# LPC55S66_cm33_core1 register map
Vendor: nxp.com; File version: 1.0
CPU: CM33 r2p0, little endian, no MPU, no FPU, VTOR, 3 interrupt priority bits
Registers are 32-bit, read-write, reset 0x0 unless marked. A register's access mark holds for its fields unless they carry their own. Offsets are from the block's base; [hi:lo] are bit positions; {n}, {i} and the like mark numbered series; 'fields as' and 'values as' point back to an identical list.

## ADC0 — ADC
Base 0x400A0000
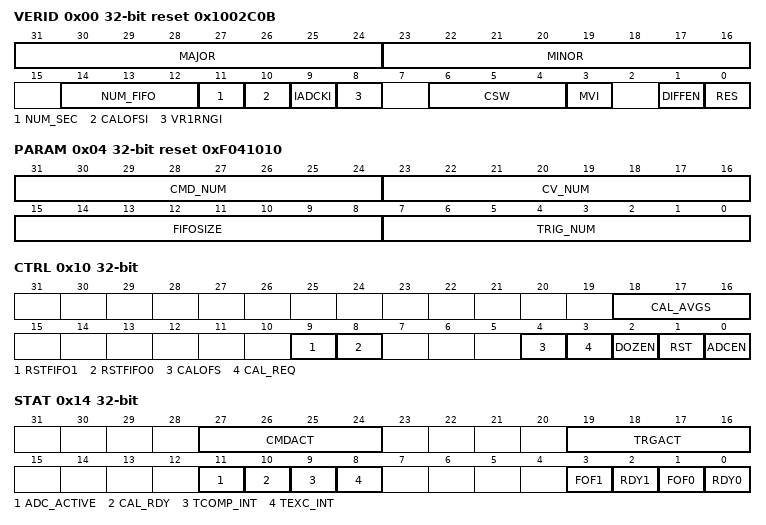
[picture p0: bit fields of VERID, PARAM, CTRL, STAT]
0x00 VERID ro reset 0x1002C0B — Version ID Register
  [31:24] MAJOR — Major Version Number
  [23:16] MINOR — Minor Version Number
  [14:12] NUM_FIFO — Number of FIFOs
    0=N/A; 1=This design supports one result FIFO; 2=This design supports two result FIFOs; 3=This design supports three result FIFOs; 4=This design supports four result FIFOs
  [11] NUM_SEC — Number of Single Ended Outputs Supported
    0=This design supports one single ended conversion at a time; 1=This design supports two simultanious single ended conversions
  [10] CALOFSI — Calibration Function Implemented
    0=Calibration Not Implemented; 1=Calibration Implemented
  [9] IADCKI — Internal ADC Clock implemented
    0=Internal clock source not implemented; 1=Internal clock source (and CFG[ADCKEN]) implemented
  [8] VR1RNGI — Voltage Reference 1 Range Control Bit Implemented
    0=Range control not required. CFG[VREF1RNG] is not implemented.; 1=Range control required. CFG[VREF1RNG] is implemented.
  [6:4] CSW — Channel Scale Width
    0=Channel scaling not supported; 1=Channel scaling supported. 1-bit CSCALE control field.; 6=Channel scaling supported. 6-bit CSCALE control field.
  [3] MVI — Multi Vref Implemented
    0=Single voltage reference high (VREFH) input supported; 1=Multiple voltage reference high (VREFH) inputs supported
  [1] DIFFEN — Differential Supported
    0=Differential operation not supported; 1=Differential operation supported. CMDLa[CTYPE] controls fields implemented.
  [0] RES — Resolution
    0=Up to 13-bit differential/12-bit single ended resolution supported; 1=Up to 16-bit differential/16-bit single ended resolution supported
0x04 PARAM ro reset 0xF041010 — Parameter Register
  [31:24] CMD_NUM — Command Buffer Number
  [23:16] CV_NUM — Compare Value Number
  [15:8] FIFOSIZE — Result FIFO Depth
    1=Result FIFO depth = 1 dataword; 4=Result FIFO depth = 4 datawords; 8=Result FIFO depth = 8 datawords; 16=Result FIFO depth = 16 datawords; 32=Result FIFO depth = 32 datawords; 64=Result FIFO depth = 64 datawords
  [7:0] TRIG_NUM — Trigger Number
0x10 CTRL — ADC Control Register
  [18:16] CAL_AVGS — Auto-Calibration Averages
    0=Single conversion; 1=2 conversions averaged; 2=4 conversions averaged; 3=8 conversions averaged; 4=16 conversions averaged; 5=32 conversions averaged; 6=64 conversions averaged; 7=128 conversions averaged
  [9] RSTFIFO1 — Reset FIFO 1
    0=No effect; 1=FIFO 1 is reset
  [8] RSTFIFO0 — Reset FIFO 0
    0=No effect; 1=FIFO 0 is reset
  [4] CALOFS — Configure for offset calibration function
    0=Calibration function disabled; 1=Request for offset calibration function
  [3] CAL_REQ — Auto-Calibration Request
    0=No request for auto-calibration has been made; 1=A request for auto-calibration has been made
  [2] DOZEN — Doze Enable
    0=ADC is enabled in Doze mode; 1=ADC is disabled in Doze mode
  [1] RST — Software Reset
    0=ADC logic is not reset; 1=ADC logic is reset
  [0] ADCEN — ADC Enable
    0=ADC is disabled; 1=ADC is enabled
0x14 STAT — ADC Status Register
  [27:24] CMDACT ro — Command Active
    0=No command is currently in progress; 1=Command 1 currently being executed; 2=Command 2 currently being executed; {v}=Associated command number is currently being executed (v=3..9)
  [19:16] TRGACT ro — Trigger Active
    0=Command (sequence) associated with Trigger 0 currently being executed; 1=Command (sequence) associated with Trigger 1 currently being executed; 2=Command (sequence) associated with Trigger 2 currently being executed; {v}=Command (sequence) from the associated Trigger number is currently being executed (v=3..9)
  [11] ADC_ACTIVE ro
    0=The ADC is IDLE. There are no pending triggers to service and no active commands are being processed.; 1=The ADC is processing a conversion, running through the power up delay, or servicing a trigger
  [10] CAL_RDY ro — Calibration Ready
    0=Calibration is incomplete or hasn't been ran; 1=The ADC is calibrated
  [9] TCOMP_INT write-1-clears — Interrupt Flag For Trigger Completion
    0=Either IE[TCOMP_IE] is set to 0, or no trigger sequences have run to completion; 1=Trigger sequence has been completed and all data is stored in the associated FIFO
  [8] TEXC_INT write-1-clears — Interrupt Flag For High Priority Trigger Exception
    0=No trigger exceptions have occurred; 1=A trigger exception has occurred and is pending acknowledgement
  [3] FOF1 write-1-clears — Result FIFO1 Overflow Flag
    0=No result FIFO1 overflow has occurred since the last time the flag was cleared; 1=At least one result FIFO1 overflow has occurred since the last time the flag was cleared
  [2] RDY1 ro — Result FIFO1 Ready Flag
    0=Result FIFO1 data level not above watermark level; 1=Result FIFO1 holding data above watermark level
  [1] FOF0 write-1-clears — Result FIFO 0 Overflow Flag
    0=No result FIFO 0 overflow has occurred since the last time the flag was cleared; 1=At least one result FIFO 0 overflow has occurred since the last time the flag was cleared
  [0] RDY0 ro — Result FIFO 0 Ready Flag
    0=Result FIFO 0 data level not above watermark level; 1=Result FIFO 0 holding data above watermark level
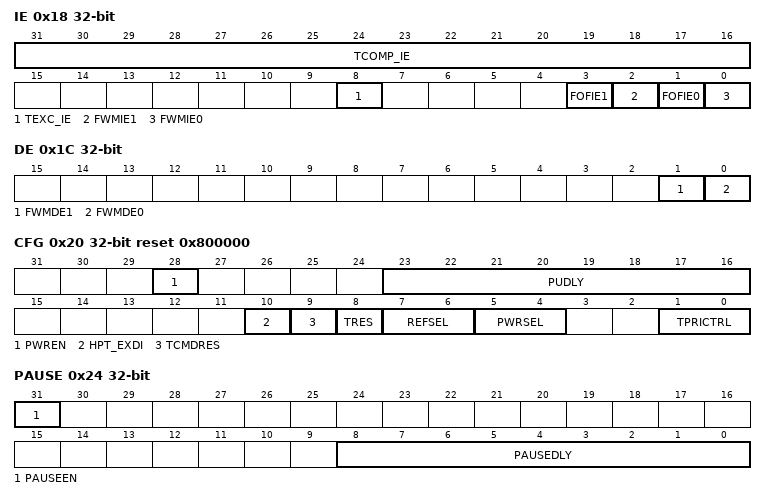
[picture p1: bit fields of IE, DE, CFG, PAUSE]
0x18 IE — Interrupt Enable Register
  [31:16] TCOMP_IE — Trigger Completion Interrupt Enable
    0=Trigger completion interrupts are disabled; 1=Trigger completion interrupts are enabled for trigger source 0 only; 2=Trigger completion interrupts are enabled for trigger source 1 only; {v}=Associated trigger completion interrupts are enabled (v=3..9); 0xFFFF=Trigger completion interrupts are enabled for every trigger source
  [8] TEXC_IE — Trigger Exception Interrupt Enable
    0=Trigger exception interrupts are disabled; 1=Trigger exception interrupts are enabled
  [3] FOFIE1 — Result FIFO1 Overflow Interrupt Enable
    values as STAT.FOF1
  [2] FWMIE1 — FIFO1 Watermark Interrupt Enable
    0=FIFO1 watermark interrupts are not enabled; 1=FIFO1 watermark interrupts are enabled
  [1] FOFIE0 — Result FIFO 0 Overflow Interrupt Enable
    0=FIFO 0 overflow interrupts are not enabled; 1=FIFO 0 overflow interrupts are enabled
  [0] FWMIE0 — FIFO 0 Watermark Interrupt Enable
    0=FIFO 0 watermark interrupts are not enabled; 1=FIFO 0 watermark interrupts are enabled
0x1C DE — DMA Enable Register
  [1] FWMDE1 — FIFO1 Watermark DMA Enable
    0=DMA request disabled; 1=DMA request enabled
  [0] FWMDE0 — FIFO 0 Watermark DMA Enable
    0=DMA request disabled; 1=DMA request enabled
0x20 CFG reset 0x800000 — ADC Configuration Register
  [28] PWREN — ADC Analog Pre-Enable
    0=ADC analog circuits are only enabled while conversions are active. Performance is affected due to analog startup delays.; 1=ADC analog circuits are pre-enabled and ready to execute conversions without startup delays (at the cost of higher DC current consumption). A single power up delay (CFG[PUDLY]) is executed immediately once PWREN is set, and any detected trigger does not begin ADC operation until the power up delay time has passed. After this initial delay expires the analog will remain pre-enabled, and no additional delays will be executed.
  [23:16] PUDLY — Power Up Delay
  [10] HPT_EXDI — High Priority Trigger Exception Disable
    0=High priority trigger exceptions are enabled; 1=High priority trigger exceptions are disabled
  [9] TCMDRES — Trigger Command Resume
    0=Trigger sequences interrupted by a high priority trigger exception will be automatically restarted; 1=Trigger sequences interrupted by a high priority trigger exception will be resumed from the command executing before the exception
  [8] TRES — Trigger Resume Enable
    0=Trigger sequences interrupted by a high priority trigger exception will not be automatically resumed or restarted; 1=Trigger sequences interrupted by a high priority trigger exception will be automatically resumed or restarted
  [7:6] REFSEL — Voltage Reference Selection
    0=(Default) Option 1 setting; 1=Option 2 setting; 2=Option 3 setting
  [5:4] PWRSEL — Power Configuration Select
    0=Lowest power setting; 1=Higher power setting than 0b0; 2=Higher power setting than 0b1; 3=Highest power setting
  [1:0] TPRICTRL — ADC trigger priority control
    0=If a higher priority trigger is detected during command processing, the current conversion is aborted and the new command specified by the trigger is started; 1=If a higher priority trigger is received during command processing, the current command is stopped after after completing the current conversion. If averaging is enabled, the averaging loop will be completed. However, CMDHa[LOOP] will be ignored and the higher priority trigger will be serviced.; 2=If a higher priority trigger is received during command processing, the current command will be completed (averaging, looping, compare) before servicing the higher priority trigger
0x24 PAUSE — ADC Pause Register
  [31] PAUSEEN — PAUSE Option Enable
    0=Pause operation disabled; 1=Pause operation enabled
  [8:0] PAUSEDLY — Pause Delay
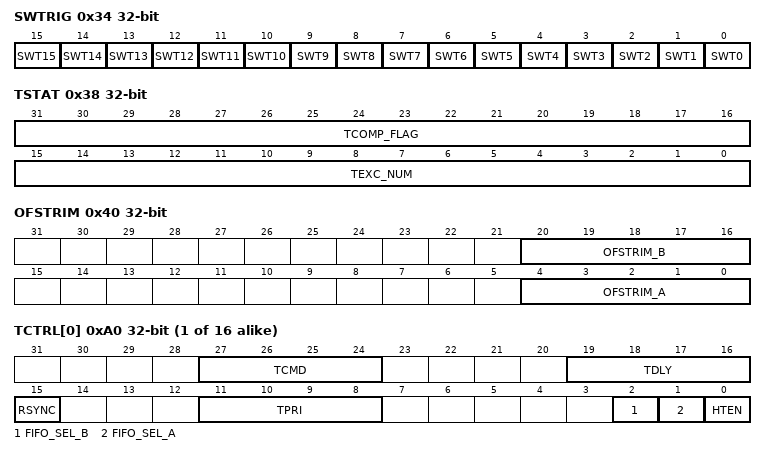
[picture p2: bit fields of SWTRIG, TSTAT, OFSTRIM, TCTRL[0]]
0x34 SWTRIG — Software Trigger Register
  [n] SWT{n} (n=0..15) — Software trigger {n} event
    0=No trigger {n} event generated; 1=Trigger {n} event generated
0x38 TSTAT — Trigger Status Register
  [31:16] TCOMP_FLAG write-1-clears — Trigger Completion Flag
    0=No triggers have been completed. Trigger completion interrupts are disabled.; 1=Trigger 0 has been completed and triger 0 has enabled completion interrupts; 2=Trigger 1 has been completed and triger 1 has enabled completion interrupts; {v}=Associated trigger sequence has completed and has enabled completion interrupts (v=3..9); 0xFFFF=Every trigger sequence has been completed and every trigger has enabled completion interrupts
  [15:0] TEXC_NUM write-1-clears — Trigger Exception Number
    0=No triggers have been interrupted by a high priority exception. Or CFG[TRES] = 1.; 1=Trigger 0 has been interrupted by a high priority exception; 2=Trigger 1 has been interrupted by a high priority exception; {v}=Associated trigger sequence has interrupted by a high priority exception (v=3..9); 0xFFFF=Every trigger sequence has been interrupted by a high priority exception
0x40 OFSTRIM — ADC Offset Trim Register
  [20:16] OFSTRIM_B — Trim for offset
  [4:0] OFSTRIM_A — Trim for offset
{0xA0+4i} TCTRL[{i}] (i=0..15) — Trigger Control Register
  [27:24] TCMD — Trigger command select
    0=Not a valid selection from the command buffer. Trigger event is ignored.; 1=CMD1 is executed; {v}=Corresponding CMD is executed (v=2..9); 15=CMD15 is executed
  [19:16] TDLY — Trigger delay select
  [15] RSYNC — Trigger Resync
  [11:8] TPRI — Trigger priority setting
    0=Set to highest priority, Level 1; {v}=Set to corresponding priority level (v=1..9); 15=Set to lowest priority, Level 16
  [2] FIFO_SEL_B — SAR Result Destination For Channel B
    0=Result written to FIFO 0; 1=Result written to FIFO 1
  [1] FIFO_SEL_A — SAR Result Destination For Channel A
    0=Result written to FIFO 0; 1=Result written to FIFO 1
  [0] HTEN — Trigger enable
    0=Hardware trigger source disabled; 1=Hardware trigger source enabled
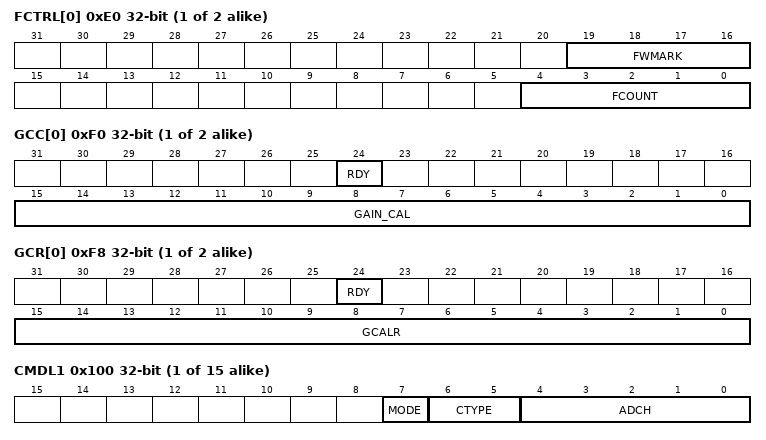
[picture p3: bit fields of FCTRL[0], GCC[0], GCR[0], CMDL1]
{0xE0+4i} FCTRL[{i}] (i=0..1) — FIFO Control Register
  [19:16] FWMARK — Watermark level selection
  [4:0] FCOUNT ro — Result FIFO counter
{0xF0+4i} GCC[{i}] (i=0..1) ro — Gain Calibration Control
  [24] RDY — Gain Calibration Value Valid
    0=The gain calibration value is invalid. Run the auto-calibration routine for this value to be written.; 1=The gain calibration value is valid. It should be used to update the GCRa[GCALR] register field.
  [15:0] GAIN_CAL — Gain Calibration Value
{0xF8+4i} GCR[{i}] (i=0..1) — Gain Calculation Result
  [24] RDY — Gain Calculation Ready
    0=The gain offset calculation value is invalid; 1=The gain calibration value is valid
  [15:0] GCALR — Gain Calculation Result
{0xF8+8i} CMDL{i} (i=1..15) — ADC Command Low Buffer Register
  [7] MODE — Select resolution of conversions
    0=Standard resolution. Single-ended 12-bit conversion; Differential 13-bit conversion with 2's complement output.; 1=High resolution. Single-ended 16-bit conversion; Differential 16-bit conversion with 2's complement output.
  [6:5] CTYPE — Conversion Type
    0=Single-Ended Mode. Only A side channel is converted.; 1=Single-Ended Mode. Only B side channel is converted.; 2=Differential Mode. A-B.; 3=Dual-Single-Ended Mode. Both A side and B side channels are converted independently.
  [4:0] ADCH — Input channel select
    {v}=Select CH{v}A or CH{v}B or CH{v}A/CH{v}B pair (v=0..3); {v}=Select corresponding channel CHnA or CHnB or CHnA/CHnB pair (v=4..9); 30=Select CH30A or CH30B or CH30A/CH30B pair; 31=Select CH31A or CH31B or CH31A/CH31B pair
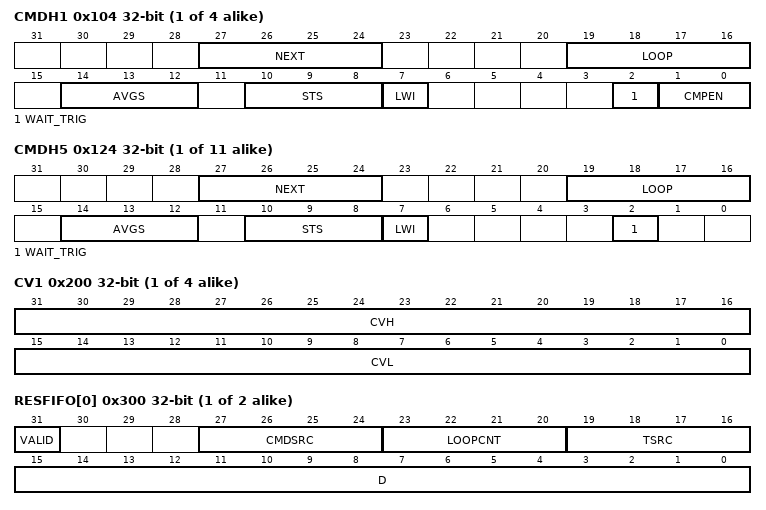
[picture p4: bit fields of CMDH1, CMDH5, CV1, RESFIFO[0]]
{0xFC+8i} CMDH{i} (i=1..4) — ADC Command High Buffer Register
  [27:24] NEXT — Next Command Select
    0=No next command defined. Terminate conversions at completion of current command. If lower priority trigger pending, begin command associated with lower priority trigger.; 1=Select CMD1 command buffer register as next command; {v}=Select corresponding CMD command buffer register as next command (v=2..9); 15=Select CMD15 command buffer register as next command
  [19:16] LOOP — Loop Count Select
    0=Looping not enabled. Command executes 1 time.; 1=Loop 1 time. Command executes 2 times.; 2=Loop 2 times. Command executes 3 times.; {v}=Loop corresponding number of times. Command executes LOOP+1 times. (v=3..9); 15=Loop 15 times. Command executes 16 times.
  [14:12] AVGS — Hardware Average Select
    values as CTRL.CAL_AVGS
  [10:8] STS — Sample Time Select
    0=Minimum sample time of 3 ADCK cycles; 1=3 + 21 ADCK cycles; 5 ADCK cycles total sample time; 2=3 + 22 ADCK cycles; 7 ADCK cycles total sample time; 3=3 + 23 ADCK cycles; 11 ADCK cycles total sample time; 4=3 + 24 ADCK cycles; 19 ADCK cycles total sample time; 5=3 + 25 ADCK cycles; 35 ADCK cycles total sample time; 6=3 + 26 ADCK cycles; 67 ADCK cycles total sample time; 7=3 + 27 ADCK cycles; 131 ADCK cycles total sample time
  [7] LWI — Loop with Increment
    0=Auto channel increment disabled; 1=Auto channel increment enabled
  [2] WAIT_TRIG — Wait for trigger assertion before execution.
    0=This command will be automatically executed; 1=The active trigger must be asserted again before executing this command
  [1:0] CMPEN — Compare Function Enable
    0=Compare disabled; 2=Compare enabled. Store on true.; 3=Compare enabled. Repeat channel acquisition (sample/convert/compare) until true.
{0xFC+8i} CMDH{i} (i=5..15) — ADC Command High Buffer Register
  [27:24] NEXT — Next Command Select
    values as CMDH1.NEXT
  [19:16] LOOP — Loop Count Select
    values as CMDH1.LOOP
  [14:12] AVGS — Hardware Average Select
    values as CTRL.CAL_AVGS
  [10:8] STS — Sample Time Select
    values as CMDH1.STS
  [7] LWI — Loop with Increment
    values as CMDH1.LWI
  [2] WAIT_TRIG — Wait for trigger assertion before execution.
    values as CMDH1.WAIT_TRIG
{0x1FC+4i} CV{i} (i=1..4) — Compare Value Register
  [31:16] CVH — Compare Value High.
  [15:0] CVL — Compare Value Low.
{0x300+4i} RESFIFO[{i}] (i=0..1) ro — ADC Data Result FIFO Register
  [31] VALID — FIFO entry is valid
    0=FIFO is empty. Discard any read from RESFIFO.; 1=FIFO record read from RESFIFO is valid
  [27:24] CMDSRC — Command Buffer Source
    0=Not a valid value CMDSRC value for a dataword in RESFIFO. 0x0 is only found in initial FIFO state prior to an ADC conversion result dataword being stored to a RESFIFO buffer.; 1=CMD1 buffer used as control settings for this conversion; {v}=Corresponding command buffer used as control settings for this conversion (v=2..9); 15=CMD15 buffer used as control settings for this conversion
  [23:20] LOOPCNT — Loop count value
    0=Result is from initial conversion in command; 1=Result is from second conversion in command; {v}=Result is from LOOPCNT+1 conversion in command (v=2..9); 15=Result is from 16th conversion in command
  [19:16] TSRC — Trigger Source
    0=Trigger source 0 initiated this conversion; 1=Trigger source 1 initiated this conversion; {v}=Corresponding trigger source initiated this conversion (v=2..9); 15=Trigger source 15 initiated this conversion
  [15:0] D — Data result
{0x400+4i} CAL_GAR[{i}] (i=0..32) — Calibration General A-Side Registers
  [15:0] CAL_GAR_VAL — Calibration General A Side Register Element
{0x500+4i} CAL_GBR[{i}] (i=0..32) — Calibration General B-Side Registers
  [15:0] CAL_GBR_VAL — Calibration General B Side Register Element
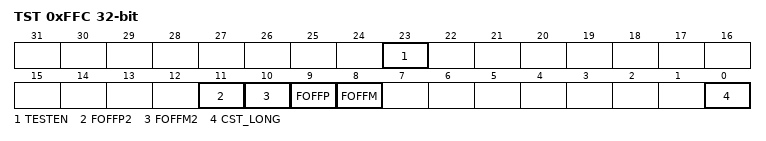
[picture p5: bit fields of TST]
0xFFC TST — ADC Test Register
  [23] TESTEN — Enable test configuration
    0=Normal operation. Test configuration not enabled.; 1=Hardware BIST Test in progress
  [11] FOFFP2 — Force P-side negative offset
    0=Normal operation. No forced offset.; 1=Test configuration. Forced negative offset on PDAC.
  [10] FOFFM2 — Force M-side negative offset
    0=Normal operation. No forced offset.; 1=Test configuration. Forced negative offset on MDAC.
  [9] FOFFP — Force P-side positive offset
    0=Normal operation. No forced offset.; 1=Test configuration. Forced positive offset on PDAC.
  [8] FOFFM — Force M-side positive offset
    0=Normal operation. No forced offset.; 1=Test configuration. Forced positive offset on MDAC.
  [0] CST_LONG — Calibration Sample Time Long
    0=Normal sample time. Minimum sample time of 3 ADCK cycles.; 1=Increased sample time. 67 ADCK cycles total sample time.
